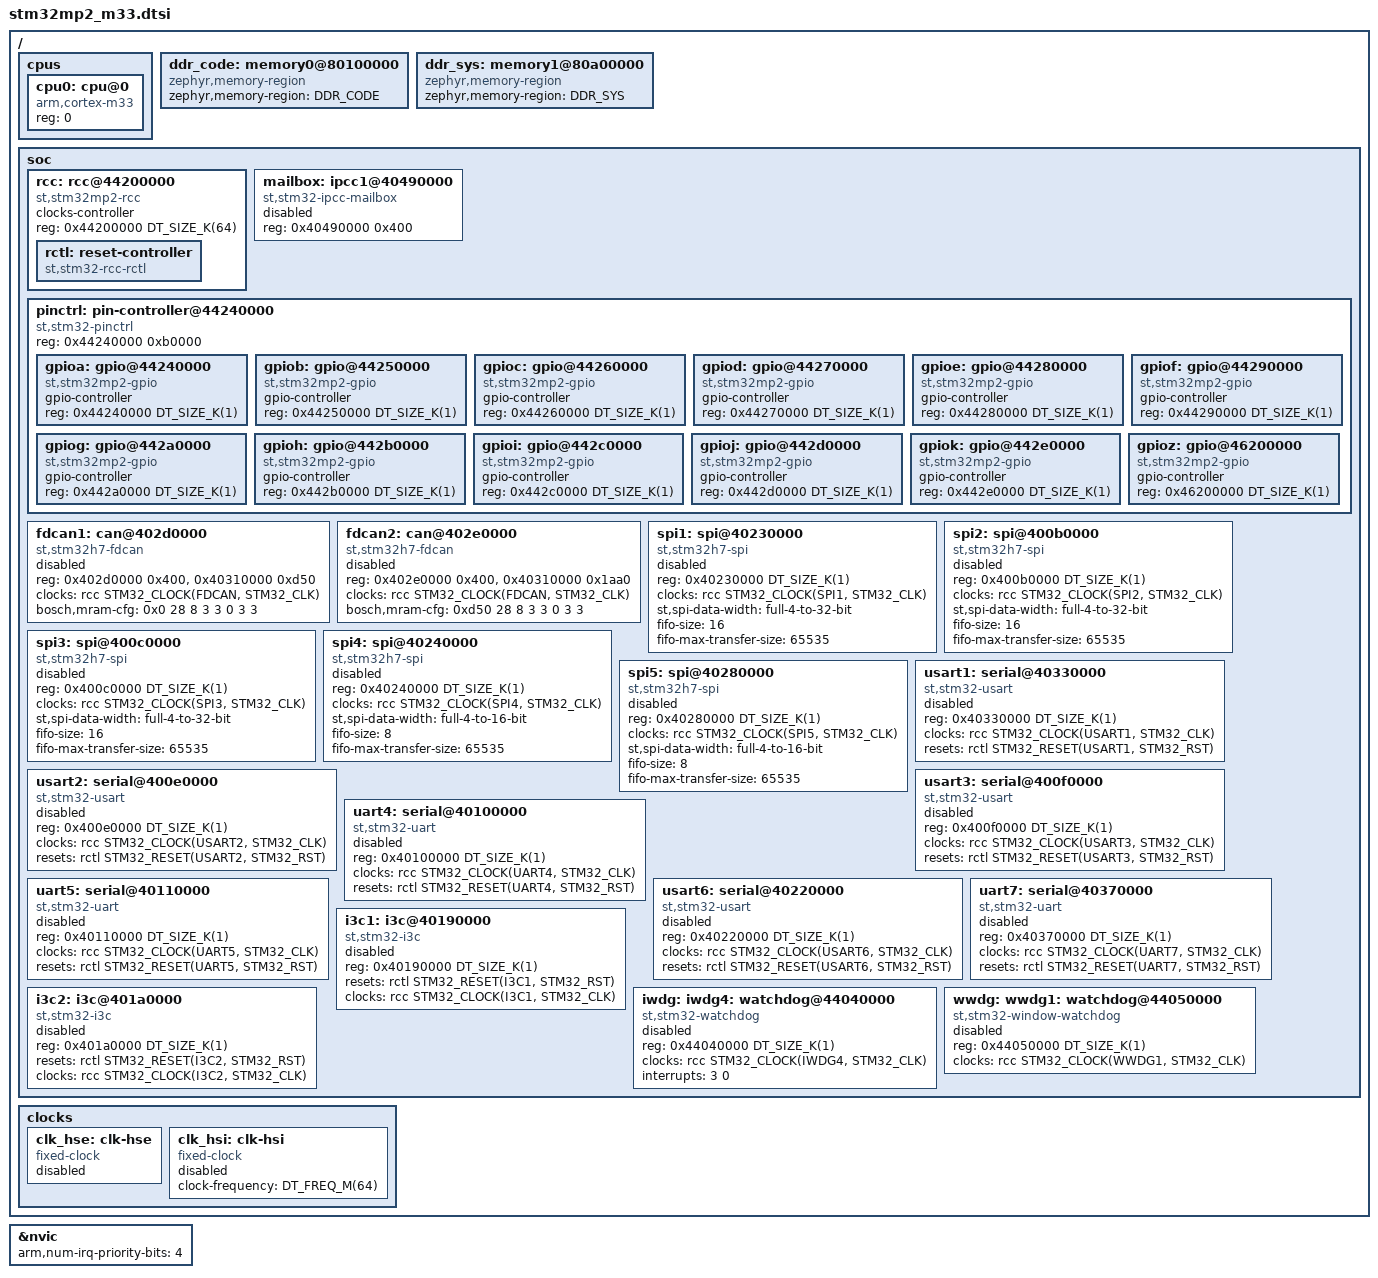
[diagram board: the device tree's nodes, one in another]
/*
 * Copyright (C) 2025 Savoir-faire Linux, Inc.
 *
 * SPDX-License-Identifier: Apache-2.0
 */

#include <arm/armv8-m.dtsi>
#include <freq.h>
#include <mem.h>
#include <zephyr/dt-bindings/gpio/gpio.h>
#include <zephyr/dt-bindings/clock/stm32mp2_clock.h>
#include <zephyr/dt-bindings/reset/stm32mp2_reset.h>
#include <zephyr/dt-bindings/i2c/i2c.h>

/ {
	cpus {
		#address-cells = <1>;
		#size-cells = <0>;

		cpu0: cpu@0 {
			device_type = "cpu";
			compatible = "arm,cortex-m33";
			reg = <0>;
		};
	};

	ddr_code: memory0@80100000 {
		compatible = "zephyr,memory-region", "mmio-sram";
		zephyr,memory-region = "DDR_CODE";
	};

	ddr_sys: memory1@80a00000 {
		compatible = "zephyr,memory-region", "mmio-sram";
		zephyr,memory-region = "DDR_SYS";
	};

	soc {
		rcc: rcc@44200000 {
			compatible = "st,stm32mp2-rcc";
			clocks-controller;
			#clock-cells = <2>;
			reg = <0x44200000 DT_SIZE_K(64)>;

			rctl: reset-controller {
				compatible = "st,stm32-rcc-rctl";
				#reset-cells = <1>;
			};
		};

		mailbox: ipcc1@40490000 {
			compatible = "st,stm32-ipcc-mailbox";
			reg = <0x40490000 0x400>;
			status = "disabled";
		};

		pinctrl: pin-controller@44240000 {
			compatible = "st,stm32-pinctrl";
			#address-cells = <1>;
			#size-cells = <1>;
			reg = <0x44240000 0xb0000>;

			gpioa: gpio@44240000 {
				compatible = "st,stm32mp2-gpio";
				gpio-controller;
				#gpio-cells = <2>;
				reg = <0x44240000 DT_SIZE_K(1)>;
			};

			gpiob: gpio@44250000 {
				compatible = "st,stm32mp2-gpio";
				gpio-controller;
				#gpio-cells = <2>;
				reg = <0x44250000 DT_SIZE_K(1)>;
			};

			gpioc: gpio@44260000 {
				compatible = "st,stm32mp2-gpio";
				gpio-controller;
				#gpio-cells = <2>;
				reg = <0x44260000 DT_SIZE_K(1)>;
			};

			gpiod: gpio@44270000 {
				compatible = "st,stm32mp2-gpio";
				gpio-controller;
				#gpio-cells = <2>;
				reg = <0x44270000 DT_SIZE_K(1)>;
			};

			gpioe: gpio@44280000 {
				compatible = "st,stm32mp2-gpio";
				gpio-controller;
				#gpio-cells = <2>;
				reg = <0x44280000 DT_SIZE_K(1)>;
			};

			gpiof: gpio@44290000 {
				compatible = "st,stm32mp2-gpio";
				gpio-controller;
				#gpio-cells = <2>;
				reg = <0x44290000 DT_SIZE_K(1)>;
			};

			gpiog: gpio@442a0000 {
				compatible = "st,stm32mp2-gpio";
				gpio-controller;
				#gpio-cells = <2>;
				reg = <0x442a0000 DT_SIZE_K(1)>;
			};

			gpioh: gpio@442b0000 {
				compatible = "st,stm32mp2-gpio";
				gpio-controller;
				#gpio-cells = <2>;
				reg = <0x442b0000 DT_SIZE_K(1)>;
			};

			gpioi: gpio@442c0000 {
				compatible = "st,stm32mp2-gpio";
				gpio-controller;
				#gpio-cells = <2>;
				reg = <0x442c0000 DT_SIZE_K(1)>;
			};

			gpioj: gpio@442d0000 {
				compatible = "st,stm32mp2-gpio";
				gpio-controller;
				#gpio-cells = <2>;
				reg = <0x442d0000 DT_SIZE_K(1)>;
			};

			gpiok: gpio@442e0000 {
				compatible = "st,stm32mp2-gpio";
				gpio-controller;
				#gpio-cells = <2>;
				reg = <0x442e0000 DT_SIZE_K(1)>;
			};

			gpioz: gpio@46200000 {
				compatible = "st,stm32mp2-gpio";
				gpio-controller;
				#gpio-cells = <2>;
				reg = <0x46200000 DT_SIZE_K(1)>;
			};
		};

		fdcan1: can@402d0000 {
			compatible = "st,stm32h7-fdcan";
			reg = <0x402d0000 0x400>, <0x40310000 0xd50>;
			reg-names = "m_can", "message_ram";
			clocks = <&rcc STM32_CLOCK(FDCAN, STM32_CLK)>;
			bosch,mram-cfg = <0x0 28 8 3 3 0 3 3>;
			status = "disabled";
		};

		fdcan2: can@402e0000 {
			compatible = "st,stm32h7-fdcan";
			reg = <0x402e0000 0x400>, <0x40310000 0x1aa0>;
			reg-names = "m_can", "message_ram";
			clocks = <&rcc STM32_CLOCK(FDCAN, STM32_CLK)>;
			bosch,mram-cfg = <0xd50 28 8 3 3 0 3 3>;
			status = "disabled";
		};

		spi1: spi@40230000 {
			compatible = "st,stm32h7-spi", "st,stm32-spi-fifo", "st,stm32-spi";
			reg = <0x40230000 DT_SIZE_K(1)>;
			#address-cells = <1>;
			#size-cells = <0>;
			clocks = <&rcc STM32_CLOCK(SPI1, STM32_CLK)>;
			st,spi-data-width = "full-4-to-32-bit";
			fifo-size = <16>;
			fifo-max-transfer-size = <65535>;
			status = "disabled";
		};

		spi2: spi@400b0000 {
			compatible = "st,stm32h7-spi", "st,stm32-spi-fifo", "st,stm32-spi";
			reg = <0x400b0000 DT_SIZE_K(1)>;
			#address-cells = <1>;
			#size-cells = <0>;
			clocks = <&rcc STM32_CLOCK(SPI2, STM32_CLK)>;
			st,spi-data-width = "full-4-to-32-bit";
			fifo-size = <16>;
			fifo-max-transfer-size = <65535>;
			status = "disabled";
		};

		spi3: spi@400c0000 {
			compatible = "st,stm32h7-spi", "st,stm32-spi-fifo", "st,stm32-spi";
			reg = <0x400c0000 DT_SIZE_K(1)>;
			#address-cells = <1>;
			#size-cells = <0>;
			clocks = <&rcc STM32_CLOCK(SPI3, STM32_CLK)>;
			st,spi-data-width = "full-4-to-32-bit";
			fifo-size = <16>;
			fifo-max-transfer-size = <65535>;
			status = "disabled";
		};

		spi4: spi@40240000 {
			compatible = "st,stm32h7-spi", "st,stm32-spi-fifo", "st,stm32-spi";
			reg = <0x40240000 DT_SIZE_K(1)>;
			#address-cells = <1>;
			#size-cells = <0>;
			clocks = <&rcc STM32_CLOCK(SPI4, STM32_CLK)>;
			st,spi-data-width = "full-4-to-16-bit";
			fifo-size = <8>;
			fifo-max-transfer-size = <65535>;
			status = "disabled";
		};

		spi5: spi@40280000 {
			compatible = "st,stm32h7-spi", "st,stm32-spi-fifo", "st,stm32-spi";
			reg = <0x40280000 DT_SIZE_K(1)>;
			#address-cells = <1>;
			#size-cells = <0>;
			clocks = <&rcc STM32_CLOCK(SPI5, STM32_CLK)>;
			st,spi-data-width = "full-4-to-16-bit";
			fifo-size = <8>;
			fifo-max-transfer-size = <65535>;
			status = "disabled";
		};

		usart1: serial@40330000 {
			compatible = "st,stm32-usart", "st,stm32-uart";
			reg = <0x40330000 DT_SIZE_K(1)>;
			clocks = <&rcc STM32_CLOCK(USART1, STM32_CLK)>;
			resets = <&rctl STM32_RESET(USART1, STM32_RST)>;
			status = "disabled";
		};

		usart2: serial@400e0000 {
			compatible = "st,stm32-usart", "st,stm32-uart";
			reg = <0x400e0000 DT_SIZE_K(1)>;
			clocks = <&rcc STM32_CLOCK(USART2, STM32_CLK)>;
			resets = <&rctl STM32_RESET(USART2, STM32_RST)>;
			status = "disabled";
		};

		usart3: serial@400f0000 {
			compatible = "st,stm32-usart", "st,stm32-uart";
			reg = <0x400f0000 DT_SIZE_K(1)>;
			clocks = <&rcc STM32_CLOCK(USART3, STM32_CLK)>;
			resets = <&rctl STM32_RESET(USART3, STM32_RST)>;
			status = "disabled";
		};

		uart4: serial@40100000 {
			compatible = "st,stm32-uart";
			reg = <0x40100000 DT_SIZE_K(1)>;
			clocks = <&rcc STM32_CLOCK(UART4, STM32_CLK)>;
			resets = <&rctl STM32_RESET(UART4, STM32_RST)>;
			status = "disabled";
		};

		uart5: serial@40110000 {
			compatible = "st,stm32-uart";
			reg = <0x40110000 DT_SIZE_K(1)>;
			clocks = <&rcc STM32_CLOCK(UART5, STM32_CLK)>;
			resets = <&rctl STM32_RESET(UART5, STM32_RST)>;
			status = "disabled";
		};

		usart6: serial@40220000 {
			compatible = "st,stm32-usart", "st,stm32-uart";
			reg = <0x40220000 DT_SIZE_K(1)>;
			clocks = <&rcc STM32_CLOCK(USART6, STM32_CLK)>;
			resets = <&rctl STM32_RESET(USART6, STM32_RST)>;
			status = "disabled";
		};

		uart7: serial@40370000 {
			compatible = "st,stm32-uart";
			reg = <0x40370000 DT_SIZE_K(1)>;
			clocks = <&rcc STM32_CLOCK(UART7, STM32_CLK)>;
			resets = <&rctl STM32_RESET(UART7, STM32_RST)>;
			status = "disabled";
		};

		i3c1: i3c@40190000 {
			compatible = "st,stm32-i3c";
			reg = <0x40190000 DT_SIZE_K(1)>;
			#address-cells = <3>;
			#size-cells = <0>;
			resets = <&rctl STM32_RESET(I3C1, STM32_RST)>;
			clocks = <&rcc STM32_CLOCK(I3C1, STM32_CLK)>;
			interrupt-names = "combined";
			status = "disabled";
		};

		i3c2: i3c@401a0000 {
			compatible = "st,stm32-i3c";
			reg = <0x401a0000 DT_SIZE_K(1)>;
			#address-cells = <3>;
			#size-cells = <0>;
			resets = <&rctl STM32_RESET(I3C2, STM32_RST)>;
			clocks = <&rcc STM32_CLOCK(I3C2, STM32_CLK)>;
			interrupt-names = "combined";
			status = "disabled";
		};

		iwdg: iwdg4: watchdog@44040000 {
			compatible = "st,stm32-watchdog";
			reg = <0x44040000 DT_SIZE_K(1)>;
			clocks = <&rcc STM32_CLOCK(IWDG4, STM32_CLK)>;
			interrupts = <3 0>;
			status = "disabled";
		};

		wwdg: wwdg1: watchdog@44050000 {
			compatible = "st,stm32-window-watchdog";
			reg = <0x44050000 DT_SIZE_K(1)>;
			clocks = <&rcc STM32_CLOCK(WWDG1, STM32_CLK)>;
			status = "disabled";
		};
	};

	clocks {
		clk_hse: clk-hse {
			#clock-cells = <0>;
			compatible = "fixed-clock";
			status = "disabled";
		};

		clk_hsi: clk-hsi {
			#clock-cells = <0>;
			compatible = "fixed-clock";
			clock-frequency = <DT_FREQ_M(64)>;
			status = "disabled";
		};
	};
};

&nvic {
	arm,num-irq-priority-bits = <4>;
};
